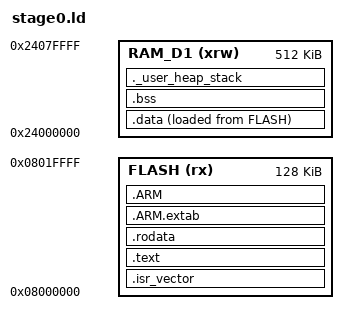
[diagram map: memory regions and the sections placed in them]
ENTRY(Reset_Handler)

_estack = ORIGIN(RAM_D1) + LENGTH(RAM_D1);
_Min_Heap_Size = 0x200;
_Min_Stack_Size = 0x800;

MEMORY
{
  FLASH (rx)    : ORIGIN = 0x08000000, LENGTH = 128K
  RAM_D1 (xrw)  : ORIGIN = 0x24000000, LENGTH = 512K
}

SECTIONS
{
  .isr_vector : { . = ALIGN(4); KEEP(*(.isr_vector)) . = ALIGN(4); } >FLASH
  .text : { . = ALIGN(4); *(.text) *(.text*) *(.glue_7) *(.glue_7t) KEEP(*(.init)) KEEP(*(.fini)) . = ALIGN(4); _etext = .; } >FLASH
  .rodata : { . = ALIGN(4); *(.rodata) *(.rodata*) . = ALIGN(4); } >FLASH
  .ARM.extab : { *(.ARM.extab* .gnu.linkonce.armextab.*) } >FLASH
  .ARM : { __exidx_start = .; *(.ARM.exidx*) __exidx_end = .; } >FLASH
  _sidata = LOADADDR(.data);
  .data : { . = ALIGN(4); _sdata = .; *(.data) *(.data*) . = ALIGN(4); _edata = .; } >RAM_D1 AT>FLASH
  .bss : { . = ALIGN(4); _sbss = .; __bss_start__ = _sbss; *(.bss) *(.bss*) *(COMMON) . = ALIGN(4); _ebss = .; __bss_end__ = _ebss; } >RAM_D1
  ._user_heap_stack : { . = ALIGN(8); PROVIDE(end = .); PROVIDE(_end = .); . = . + _Min_Heap_Size; . = . + _Min_Stack_Size; . = ALIGN(8); } >RAM_D1
  /DISCARD/ : { libc.a(*) libm.a(*) libgcc.a(*) }
  .ARM.attributes 0 : { *(.ARM.attributes) }
}
